# CC2538NF53 register map
File version: 1.0
System-on-Chip Solution for 2.4-GHz IEEE 802.15.4 and ZigBee®/ZigBee IP® Applications
CPU: CM3 1.0, other endian, MPU, FPU, 3 interrupt priority bits
Registers are 32-bit, read-write, reset 0x0 unless marked. A register's access mark holds for its fields unless they carry their own. Offsets are from the block's base; lines under a group give offsets from that group; [hi:lo] are bit positions; {n}, {i} and the like mark numbered series; 'fields as' and 'values as' point back to an identical list; <NAME> marks a mode.

## Memory map
0x40008000 SSI0 size 0x1000 — Register fields should be considered static unless otherwise noted as dynamic.
0x40009000 SSI1 size 0x1000 — Register fields should be considered static unless otherwise noted as dynamic.
0x4000C000 UART0 size 0x1000 — Register fields should be considered static unless otherwise noted as dynamic.
0x4000D000 UART1 size 0x1000 — Register fields should be considered static unless otherwise noted as dynamic.
0x40020000 I2CM size 0x100 — Register fields should be considered static unless otherwise noted as dynamic.
0x40020800 I2CS size 0x100 — Register fields should be considered static unless otherwise noted as dynamic.
0x40030000 GPTIMER0 size 0x1000 — Register fields should be considered static unless otherwise noted as dynamic.
0x40031000 GPTIMER1 size 0x1000 — Register fields should be considered static unless otherwise noted as dynamic.
0x40032000 GPTIMER2 size 0x1000 — Register fields should be considered static unless otherwise noted as dynamic.
0x40033000 GPTIMER3 size 0x1000 — Register fields should be considered static unless otherwise noted as dynamic.
0x40088500 RFCORE_FFSM size 0x100 — Register fields should be considered static unless otherwise noted as dynamic.
0x40088600 RFCORE_XREG size 0x200 — Register fields should be considered static unless otherwise noted as dynamic.
0x40088800 RFCORE_SFR size 0x100 — Register fields should be considered static unless otherwise noted as dynamic.
0x40089000 USB size 0x100 — Register fields should be considered static unless otherwise noted as dynamic.
0x4008B000 AES size 0x1000 — Register fields should be considered static unless otherwise noted as dynamic.
0x400D2000 SYS_CTRL size 0x100 — Register fields should be considered static unless otherwise noted as dynamic.
0x400D3000 FLASH_CTRL size 0x100 — Register fields should be considered static unless otherwise noted as dynamic.
0x400D4000 IOC size 0x154 — Register fields should be considered static unless otherwise noted as dynamic.
0x400D5000 SMWDTHROSC size 0x100 — Register fields should be considered static unless otherwise noted as dynamic.
0x400D6000 ANA_REGS size 0x100 — Register fields should be considered static unless otherwise noted as dynamic.
0x400D7000 SOC_ADC size 0x100 — Register fields should be considered static unless otherwise noted as dynamic.
0x400D9000 GPIO_A size 0x1000 — Register fields should be considered static unless otherwise noted as dynamic.
0x400DA000 GPIO_B size 0x1000 — Register fields should be considered static unless otherwise noted as dynamic.
0x400DB000 GPIO_C size 0x1000 — Register fields should be considered static unless otherwise noted as dynamic.
0x400DC000 GPIO_D size 0x1000 — Register fields should be considered static unless otherwise noted as dynamic.
0x400FF000 UDMA size 0x1000 — Register fields should be considered static unless otherwise noted as dynamic.
0x40110000 STTEST size 0x100 — Register fields should be considered static unless otherwise noted as dynamic.
0x44010000 CCTEST size 0x100 — Register fields should be considered static unless otherwise noted as dynamic.

## SMWDTHROSC — Register fields should be considered static unless otherwise noted as dynamic.
Base 0x400D5000
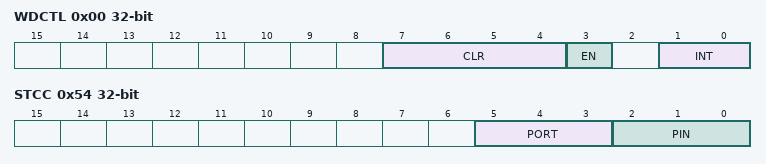
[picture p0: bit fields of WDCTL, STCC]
0x00 WDCTL — Watchdog Timer Control
  [7:4] CLR — [7:4] Clear timer When 0xA followed by 0x5 is written to these bits, the timer is loaded with 0x0000. Note that 0x5 must be written within one watchdog clock period Twdt after 0xA was written for the clearing to take effect (ensured). If 0x5 is written between Twdt and 2Twdt after 0xA was written, the clearing may take effect, but there is no guarantee. If 0x5 is written > 2Twdt after 0xA was written, the timer will not be cleared. If a value other than 0x5 is written after 0xA has been written, the clear sequence is aborted. If 0xA is written, this starts a new clear sequence. Writing to these bits when EN = 0 has no effect.
  [3] EN — [3:3] Enable timer When 1 is written to this bit the timer is enabled and starts incrementing. The interval setting specified by INT[1:0] is used. Writing 0 to this bit have no effect.
  [1:0] INT — [1:0] Timer interval select These bits select the timer interval as follows: 00: Twdt x 32768 01: Twdt x 8192 10: Twdt x 512 11: Twdt x 64 Writing these bits when EN = 1 has no effect.
0x40 ST0 — Sleep Timer 0 count and compare
  [7:0] ST0 — [7:0] Sleep Timer count and compare value. When read, this register returns the low bits [7:0] of the Sleep Timer count. When writing this register sets the low bits [7:0] of the compare value.
0x44 ST1 — Sleep Timer 1 count and compare
  [7:0] ST1 — [7:0] Sleep Timer count and compare value When read, this register returns the middle bits [15:8] of the Sleep Timer count. When writing this register sets the middle bits [15:8] of the compare value. The value read is latched at the time of reading register ST0. The value written is latched when ST0 is written.
0x48 ST2 — Sleep Timer 2 count and compare
  [7:0] ST2 — [7:0] Sleep Timer count and compare value When read, this register returns the high bits [23:16] of the Sleep Timer count. When writing this register sets the high bits [23:16] of the compare value. The value read is latched at the time of reading register ST0. The value written is latched when ST0 is written.
0x4C ST3 — Sleep Timer 3 count and compare
  [7:0] ST3 — [7:0] Sleep Timer count and compare value When read, this register returns the high bits [31:24] of the Sleep Timer count. When writing this register sets the high bits [31:24] of the compare value. The value read is latched at the time of reading register ST0. The value written is latched when ST0 is written.
0x50 STLOAD — Sleep Timer load status
  [0] STLOAD — [0:0] Status signal for when STx registers have been uploaded to 32-kHz counter. 1: Load is complete 0: Load is busy and STx regs are blocked for writing
0x54 STCC — Sleep Timer Capture control
  [5:3] PORT — [5:3] Port select Valid settings are 0-3, all others inhibit any capture from occurring 000: Port A selected 001: Port B selected 010: Port C selected 011: Port D selected
  [2:0] PIN — [2:0] Pin select Valid settings are 1-7 when either port A, B, C, or D is selected.
0x58 STCS — Sleep Timer Capture status
  [0] VALID — [0:0] Capture valid flag Set to 1 when capture value in STCV has been updated Clear explicitly to allow new capture
{0x5C+4i} STCV{i} (i=0..2) — Sleep Timer Capture value byte {i}
  [7:0] STCV{i} — [7:0] Bits [{8i+7}:{8i}] of Sleep Timer capture value
0x68 STCV3 — Sleep Timer Capture value byte 3
  [7:0] STCV3 — [7:0] Bits [32:24] of Sleep Timer capture value
